# MINI51AN_v1 register map
File version: 1.0
Registers are 32-bit, read-write, reset 0x0 unless marked. A register's access mark holds for its fields unless they carry their own. Offsets are from the block's base; [hi:lo] are bit positions; 'fields as' and 'values as' point back to an identical list.

## CMP — CMP Register Map
Base 0x400D0000
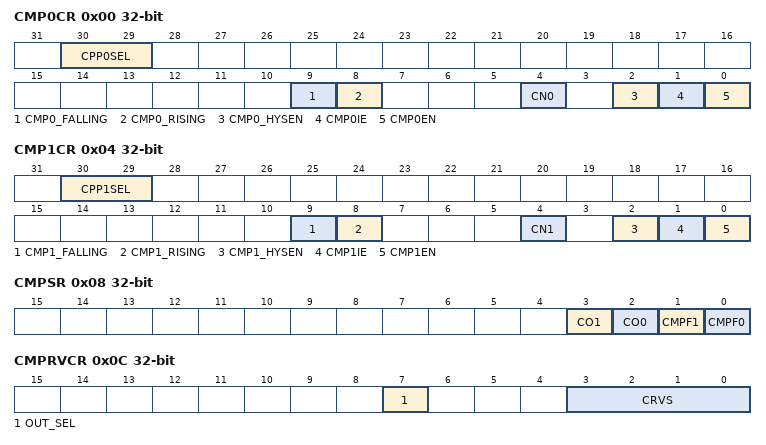
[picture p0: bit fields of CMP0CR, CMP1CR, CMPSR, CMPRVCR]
0x00 CMP0CR — Comparator0 Control Register
  [30:29] CPP0SEL — Comparator0 Positive Input Selection
    0=From P1.5; 1=From P1.0; 2=From P1.2; 3=From P1.3
  [9] CMP0_FALLING — Comparator0 Falling Edge Trigger Enable. Note: The bit is only effective while comparator0 triggers PWM/Timer.
    0=Disable comparator0 trigger PWM/Timer on falling edge; 1=Enable comparator0 trigger PWM/Timer on falling edge
  [8] CMP0_RISING — Comparator0 Trigger PWM/Timer on Rising Edge Enable. Note: The bit is only effective while comparator0 triggers PWM/Timer.
    0=Disable comparator0 trigger PWM/Timer on rising edge; 1=Enable comparator0 trigger PWM/Timer on rising edge
  [4] CN0 — Comparator0 Negative Input Selection
    0=The comparator reference pin CPN0 is selected as the negative comparator input; 1=The internal comparator reference voltage (Vref = 1.25V or from CRV setting value) is selected as the negative comparator input
  [2] CMP0_HYSEN — Comparator0 Hysteresis Enable
    0=CMP0 Hysteresis function Disabled (Default); 1=CMP0 Hysteresis function at comparator 0 Enabled that the typical range is 20mV
  [1] CMP0IE — Comparator0 Interrupt Enable. Interrupt is generated if CMP0IE bit is set to 1 after CMP0 conversion finished.
    0=CMP0 interrupt function Disabled; 1=CMP0 interrupt function Enabled
  [0] CMP0EN — Comparator0 Enable. Comparator output needs to wait 10 us stable time after CMP0EN is set.
    0=Disabled; 1=Enabled
0x04 CMP1CR — Comparator1 Control Register
  [30:29] CPP1SEL — Comparator1 Positive Input Selection
    0=From P3.1; 1=From P3.2; 2=From P3.4; 3=From P3.5
  [9] CMP1_FALLING — Comparator1 Falling Edge Trigger Enable. Note: The bit is only effective while comparator1 triggers PWM/Timer.
    0=Disable comparator1 trigger PWM/Timer on falling edge; 1=Enable comparator1 trigger PWM/Timer on falling edge
  [8] CMP1_RISING — Comparator1 Trigger PWM/Timer on Rising Edge Enable. Note: The bit is only effective while comparator1 triggers PWM/Timer.
    0=Disable comparator1 trigger PWM/Timer on rising edge; 1=Enable comparator1 trigger PWM/Timer on rising edge
  [4] CN1 — Comparator1 Negative Input Selection
    0=The comparator reference pin CPN0 is selected as the negative comparator input; 1=The internal comparator reference voltage (Vref=1.25V or from CRV setting value) is selected as the negative comparator input
  [2] CMP1_HYSEN — Comparator1 Hysteresis Enable
    values as CMP0CR.CMP0_HYSEN
  [1] CMP1IE — Comparator1 Interrupt Enable. Interrupt is generated if CMP1IE bit is set to 1 after CMP1 conversion finished.
    0=CMP1 interrupt function Disabled; 1=CMP1 interrupt function Enabled
  [0] CMP1EN — Comparator1 Enable. Comparator output needs to wait 10 us stable time after CMP1EN is set.
    0=Disabled; 1=Enabled
0x08 CMPSR — Comparator Status Register
  [3] CO1 — Comparator1 Output
  [2] CO0 — Comparator0 Output
  [1] CMPF1 — Comparator1 Flag. This bit is set by hardware whenever the comparator1 output changes state. This will cause an interrupt if CMP1IE set. Software can write 1 to clear this bit to zero.
  [0] CMPF0 — Comparator0 Flag. This bit is set by hardware whenever the comparator0 output changes state. This will cause an interrupt if CMP0IE set. Software can write 1 to clear this bit to zero.
0x0C CMPRVCR — Comparator Reference Voltage Control Register
  [7] OUT_SEL — CRV Module Output Selection
    0=Band-gap 1.22 V voltage Selected; 1=CRVS setting voltage Selected
  [3:0] CRVS — Comparator Reference Voltage Setting

## FMC — FMC Register Map
Base 0x5000C000
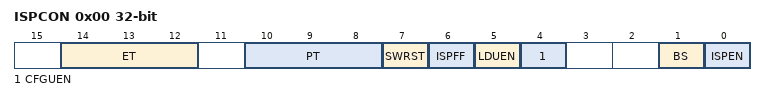
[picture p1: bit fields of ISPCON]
0x00 ISPCON — ISP Control Register
  [14:12] ET — Flash Erase Time
  [10:8] PT — Flash Program Time
  [7] SWRST — Software Reset. Writing 1 to this bit to start software reset. It is cleared by hardware after reset is finished.
  [6] ISPFF — ISP Fail Flag. This bit is set by hardware when a triggered ISP meets any of the following conditions: (1) APROM writes to itself. (2) LDROM writes to itself. (3) CONFIG is erased/programmed when the MCU is running in APROM. (4) Destination address is illegal, such as over an available range. Software can write 1 to clear this bit.
  [5] LDUEN — LDROM Update Enable
    0=LDROM cannot be updated; 1=LDROM can be updated when the MCU runs in APROM
  [4] CFGUEN — Enable Config-bits Update by ISP
    0=Disable ISP can update config-bits; 1=Enable ISP can update config-bits
  [1] BS — Boot Selection. Set/clear this bit to select next booting from LDROM/APROM, respectively. This bit also functions as MCU booting status flag, which can be used to check where MCU booted from. This bit is initiated with the inversed value of CBS in Config0 after power-on reset; It keeps the same value at other reset.
    0=Boot from APROM; 1=Boot from LDROM
  [0] ISPEN — ISP Enable. ISP function enable bit. Set this bit to enable ISP function.
    0=ISP function Disabled; 1=ISP function Enabled
0x04 ISPADR — ISP Address Register
  [31:0] ISPADR — ISP Address. The NuMicro Mini51TM series supports word program only. ISPADR[1:0] must be kept 00 for ISP operation.
0x08 ISPDAT — ISP Data Register
  [31:0] ISPDAT — ISP Data. Write data to this register before ISP program operation. Read data from this register after ISP read operation.
0x0C ISPCMD — ISP Command Register
  [5:0] FOEN_FCEN_FCTRL — ISP Command
0x10 ISPTRG — ISP Trigger Register
  [0] ISPGO — ISP Start Trigger. Write 1 to start ISP operation; this bit will be cleared to 0 by hardware automatically when ISP operation is finished.
    0=ISP operation finished; 1=ISP on going
0x14 DFBA ro reset 0x3800 — Data Flash Start Address
  [31:0] DFBA — Data Flash Base Address. This register indicates data flash start address. It is a read only register. The data flash start address is defined by user. Since on chip flash erase unit is 512 bytes, it is mandatory to keep bit 8-0 as 0.

## WDT — WDT Register Map
Base 0x40004000
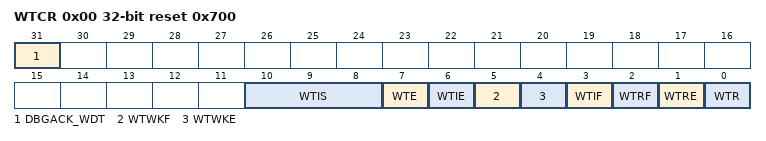
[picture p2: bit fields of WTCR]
0x00 WTCR reset 0x700 — Watchdog Timer Control Register
  [31] DBGACK_WDT — ICE Debug Mode Acknowledge Disable (write-protection bit). The Watchdog Timer counter will be held while ICE Debug mode is acknowledged.
    0=ICE Debug mode acknowledgement affects Watchdog Timer counting; 1=ICE Debug mode acknowledgement Disabled
  [10:8] WTIS — Watchdog Timer Interval Selection
  [7] WTE — Watchdog Timer Enable
    0=Watchdog Timer Disabled (this action will reset the internal counter); 1=Watchdog Timer Enabled
  [6] WTIE — Watchdog Timer Interrupt Enable
    0=Watchdog Timer interrupt Disabled; 1=Watchdog Timer interrupt Enabled
  [5] WTWKF — Watchdog Timer Wake-up Flag. If Watchdog Timer causes CPU wakes up from Power-down mode, this bit will be set to high. Software can write 1 to clear this bit.
    0=Watchdog Timer does not cause CPU wake-up; 1=CPU wake-up from sleep or Power-down mode by Watchdog time-out
  [4] WTWKE — Watchdog Timer Wake-up Function Enable bit
    0=Watchdog Timer Wake-up CPU function Disabled; 1=Wake-up function Enabled so that Watchdog Timer time-out can wake-up CPU from Power-down mode
  [3] WTIF — Watchdog Timer Interrupt Flag. If the Watchdog Timer interrupt is Enabled, hardware will set this bit to indicate that the Watchdog Timer interrupt has occurred. Note: Software can write 1 to clear this bit.
    0=Watchdog Timer interrupt does not occur; 1=Watchdog Timer interrupt occurs
  [2] WTRF — Watchdog Timer Reset Flag. When the Watchdog Timer initiates a reset, the hardware will set this bit. This flag can be read by software to determine the source of reset. Software is responsible to clear it manually by writing 1 to it. If WTRE is disabled, then the Watchdog Timer has no effect on this bit. Note: Software can write 1 to clear this bit.
    0=Watchdog Timer reset does not occur; 1=Watchdog Timer reset occurs
  [1] WTRE — Watchdog Timer Reset Enable. Setting this bit will enable the Watchdog Timer Reset function.
    0=Watchdog Timer reset function Disabled; 1=Watchdog Timer reset function Enabled
  [0] WTR — Clear Watchdog Timer. Set this bit will clear the Watchdog Timer. Note: This bit will be automatically cleared after a few clock cycles.
    0=No effect; 1=The contents of the Watchdog Timer Reset
